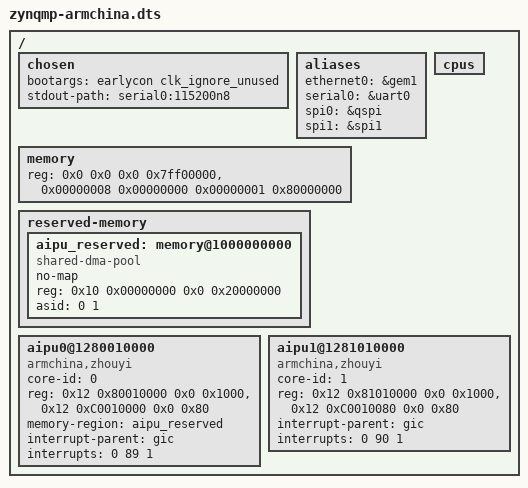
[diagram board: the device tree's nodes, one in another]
 /*
  * CAUTION: This file is automatically generated by Xilinx.
  * Version:
  * Today is: Wed Mar  6 22:27:16 2019
  */


 /dts-v1/;
 /include/ "zynqmp.dtsi"
 /include/ "zynqmp-clk-ccf.dtsi"
 ///include/ "pl.dtsi"
 /include/ "pcw.dtsi"
 / {
         chosen {
                 bootargs = "earlycon clk_ignore_unused";
                 stdout-path = "serial0:115200n8";
         };
         aliases {
                 ethernet0 = &gem1;
                 serial0 = &uart0;
                 spi0 = &qspi;
                 spi1 = &spi1;
         };
         memory {
                 device_type = "memory";
                 reg = <0x0 0x0 0x0 0x7ff00000>, <0x00000008 0x00000000 0x00000001 0x80000000>;
         };
         cpus {
                 /delete-node/ cpu@2 ;
                 /delete-node/ cpu@3 ;
         };

        reserved-memory {
                #address-cells = <2>;
                #size-cells = <2>;
                ranges;

                aipu_reserved: memory@1000000000 {
                    compatible = "shared-dma-pool";
                    no-map;
                    reg = <0x10 0x00000000 0x0 0x20000000>;
                    asid = <0 1>;
                };
        };

        aipu0@1280010000 {
               compatible = "armchina,zhouyi";
               core-id = <0>;
               reg = <0x12 0x80010000 0x0 0x1000>,
                     <0x12 0xC0010000 0x0 0x80>;
               memory-region = <&aipu_reserved>;
               interrupt-parent = <&gic>;
               interrupts = <0 89 1>; /* irq = 121 - 32 */
        };

        aipu1@1281010000 {
               compatible = "armchina,zhouyi";
               core-id = <1>;
               reg = <0x12 0x81010000 0x0 0x1000>,
                     <0x12 0xC0010080 0x0 0x80>;
               interrupt-parent = <&gic>;
               interrupts = <0 90 1>; /* irq = 122 - 32 */
        };

};
 #include "armchina-user.dtsi"
